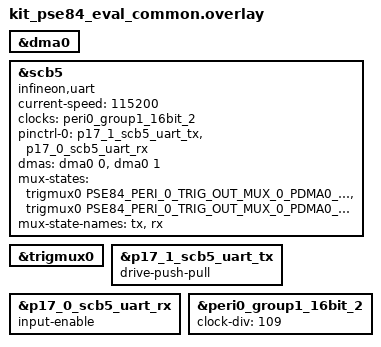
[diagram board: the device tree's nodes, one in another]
/*
 * SPDX-FileCopyrightText: Copyright (c) 2026 Infineon Technologies AG,
 * SPDX-FileCopyrightText: or an affiliate of Infineon Technologies AG. All rights reserved.
 *
 * SPDX-License-Identifier: Apache-2.0
 */

&dma0 {
	status = "okay";
};

dut: &scb5 {
	compatible = "infineon,uart";
	status = "okay";
	current-speed = <115200>;
	clocks = <&peri0_group1_16bit_2>;
	pinctrl-0 = <&p17_1_scb5_uart_tx &p17_0_scb5_uart_rx>;
	pinctrl-names = "default";
	dmas = <&dma0 0>, <&dma0 1>;
	dma-names = "tx", "rx";
	mux-states = <&trigmux0 PSE84_PERI_0_TRIG_OUT_MUX_0_PDMA0_TR_IN0 IFX_TRIGMUX_EDGE
		      PSE84_PERI_0_TRIG_IN_MUX_0_SCB_TX_TR_OUT5>,
		     <&trigmux0 PSE84_PERI_0_TRIG_OUT_MUX_0_PDMA0_TR_IN1 IFX_TRIGMUX_LEVEL
		      PSE84_PERI_0_TRIG_IN_MUX_0_SCB_RX_TR_OUT5>;
	mux-state-names = "tx", "rx";
};

&trigmux0 {
	status = "okay";
};

&p17_1_scb5_uart_tx {
	drive-push-pull;
};

&p17_0_scb5_uart_rx {
	input-enable;
};

&peri0_group1_16bit_2 {
	status = "okay";
	clock-div = <109>;
};
